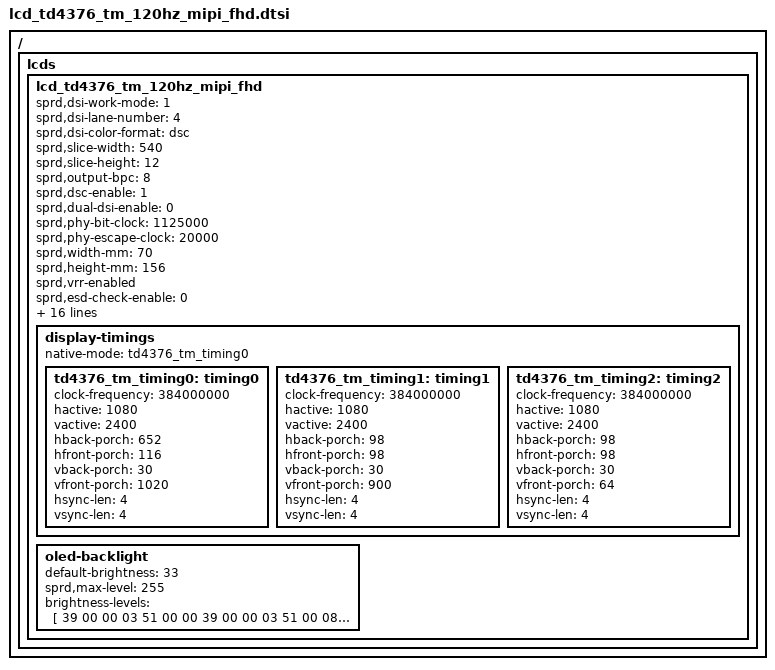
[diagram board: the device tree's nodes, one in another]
/ {
	fragment {
		target-path = "/";
		__overlay__ {
			lcds {
				lcd_td4376_tm_120hz_mipi_fhd: lcd_td4376_tm_120hz_mipi_fhd {

					sprd,dsi-work-mode = <1>; /* video burst mode*/
					sprd,dsi-lane-number = <4>;
					sprd,dsi-color-format = "dsc";
					sprd,slice-width = <540>;
					sprd,slice-height = <12>;
					sprd,output-bpc = <8>;
					sprd,dsc-enable = <1>;
					sprd,dual-dsi-enable = <0>;

					sprd,phy-bit-clock = <1125000>;
					sprd,phy-escape-clock = <20000>;/* kHz */
					sprd,width-mm = <70>;
					sprd,height-mm = <156>;
					sprd,vrr-enabled;
					sprd,esd-check-enable = <0>;
					sprd,esd-check-mode = <0>;
					sprd,esd-check-period = <2000>;
					sprd,esd-check-register = <0xA>;
					sprd,esd-check-value = <0x9c>;

					sprd,reset-on-sequence = <1 5>, <0 5>, <1 20>;
					sprd,reset-off-sequence = <0 10>;
					ontim,tp-reset-flag;
					sprd,need-execute-shutdown;
					ontim,qrcode-read-flag;
					sprd,qrcode-reg = <0xBF 27>;

					sprd,initial-command = [
						15 00 00 02 B0 04
						15 00 00 02 D6 00
						15 00 00 02 B0 00
						39 00 00 11 B6 30 6b 00 86 12 0a 13 1a 00 02 0a 0a 02 20 ff ff
						39 00 00 05 B7 51 00 00 00
						39 00 00 08 B8 57 3d 19 be 1e 0a 0a
						39 00 00 08 B9 6f 3d 28 be 3c 14 0a
						39 00 00 08 BA b5 33 41 be 64 23 0a
						39 00 00 0C BB 44 26 c3 1f 19 06 03 c0 00 00 10
						39 00 00 0C BC 32 4c c3 52 32 1f 03 f2 00 00 13
						39 00 00 0C BD 24 68 c3 aa 3f 32 03 ff 00 00 25
						39 00 00 0D BE 00 00 04 00 00 00 00 00 00 00 00 00
						39 00 00 24 C0 00 51 01 2c 08 09 60 03 BC 22 00 08 00 70 00 00 00 00 00 00 00 00 02 01 2c 01 2c 01 2c 00 00 00 00 00 00
						39 00 00 63 C1 30 00 00 61 00 00 00 00 22 00 05 20 00 80 fa 40 00 84 0f 00 00 00 00 00 00 00 00 00 00 00 00 00 00 00 00 00 00 00 00 00 00 01 2c 08 08 bf 07 d0 0b b8 0D 33 11 94 12 5c 1b 58 00 03 00 ff f5 84 7a a0 43 FE b3 4C 22 06 14 1B 62 F2 5F 0F e0 CB 2f f7 00 00 00 00 00 00 00 00 00 00 00 01 00 0e 37 d0
						39 00 00 A0 C2 00 60 20 01 04 10 05 05 00 00 00 00 00 00 00 00 00 00 00 00 00 00 00 00 00 00 00 00 60 46 04 04 01 01 c3 00 30 04 00 00 02 08 00 00 00 00 11 00 30 04 04 00 00 00 00 00 00 00 00 00 00 00 00 00 00 00 00 00 00 00 00 00 11 00 00 00 00 00 00 00 00 00 00 00 00 00 00 00 00 00 00 00 00 00 00 00 11 00 00 00 00 00 00 00 00 00 00 00 00 00 00 00 00 00 00 00 00 00 00 00 11 00 00 00 00 00 00 00 00 00 00 00 00 00 00 00 00 00 00 00 00 00 00 00 00 00 00 00 00 00 00 00 00 00 00 00 00 00 00
						39 00 00 6D C3 00 00 00 00 00 00 00 00 00 00 00 00 00 00 00 00 00 00 00 00 00 00 00 00 00 00 00 00 00 00 00 00 00 00 00 00 00 00 00 00 00 00 00 00 00 00 00 00 00 00 00 00 00 00 00 00 00 00 00 00 00 00 aa aa aa 00 00 00 00 00 00 00 00 00 00 00 00 00 00 c0 00 00 00 00 00 00 00 00 00 c0 00 00 00 00 00 00 00 00 00 00 00 00 00 00 00 00 00 00
						39 00 00 7B C4 00 00 00 5d 5f 61 00 00 00 5d 5f 61 50 02 0f 11 0e 10 bc bd 00 00 4c 51 00 00 00 5d 5f 61 00 00 00 5d 5f 61 50 02 0f 11 0e 10 bc bd 00 00 4c 51 ff ff ff ff ff ff 38 1e 4c 38 1e 4c 00 00 0c 00 00 0c 38 0e 00 38 0e 00 00 00 00 00 00 00 02 03 00 00 02 03 00 00 00 00 09 58 00 00 00 00 00 00 00 00 00 00 00 00 00 00 00 00 00 00 00 00 0E 00 00 0E 00 38 00 00 38 00 00 00
						39 00 00 06 C5 08 00 00 00 00
						39 00 00 58 C6 02 0a 43 ff ff ff ff 00 30 13 01 AF 0F 01 04 16 17 17 00 00 00 04 05 09 00 28 01 04 16 17 17 01 2b 00 00 00 1e 01 00 FF 00 00 00 00 20 20 00 00 12 00 00 00 00 00 22 22 00 00 00 00 10 00 01 00 00 00 00 01 00 00 00 00 01 00 00 00 00 05 00 1f 08 fc ff ff ff 01 00
						39 00 00 10 CB 20 80 70 00 20 00 00 2d 41 00 00 00 00 00 ff
						15 00 00 02 CD 00
						39 00 00 24 CE 5d 40 49 53 59 5e 63 68 6e 74 7e 8a 98 a8 bb d0 e7 ff 16 05 04 04 42 40 69 5a 40 40 00 00 00 84 fa 00 00
						39 00 00 07 CF 89 00 80 46 61 00
						39 00 00 13 D0 CB 1e d5 66 09 90 00 cf 0f 05 d1 e6 52 fe 09 09 c3 00
						39 00 00 3C D1 BC BC 1b b3 07 07 3b 55 35 55 35 05 77 7b 07 77 7b 78 d2 d2 06 96 BA 9C 22 22 22 b3 bb 80 00 bb bb 11 00 f8 c0 c0 c8 77 FF 11 55 55 05 55 05 55 05 55 05 77 77 77 05 05 30 33 ff
						39 00 00 18 D4 00 00 00 00 00 00 00 00 00 00 00 00 00 00 00 00 00 00 00 00 00 00 00
						39 00 00 50 D7 21 10 52 52 00 52 00 3c 10 52 04 fd 01 00 03 00 05 05 00 03 04 05 00 04 00 08 02 08 06 03 08 04 08 10 0c 0b 0a 0a 0a 07 07 06 06 00 08 08 04 05 09 00 04 04 04 04 04 04 04 00 04 04 04 04 04 04 04 04 04 04 06 06 05 05 05 00 00 00 00 00 00
						39 00 00 17 D9 40 99 26 ED 16 6C 16 6C 16 6C 00 14 00 14 00 14 01 0C 00 00 01 00
						39 00 00 05 DD 30 06 23 65
						39 00 00 0D DE 00 00 00 0F FF 00 00 00 00 10 00 51
						39 00 00 0B E6 00 00 00 00 00 00 00 00 00 00
						39 00 00 B7 E7 11 00 89 30 80 09 60 04 38 00 0c 02 1c 02 1c 02 00 02 0e 20 01 1F 00 07 0c 08 BB 08 7A 18 00 10 f0 03 0c 20 00 06 0b 0b 33 0e 1c 2a 38 46 54 62 69 70 77 79 7b 7d 7e 01 02 01 00 09 40 09 be 19 fc 19 fa 19 f8 1a 38 1a 78 1a b6 2a f6 2b 34 2b 74 3b 74 6b f4 00 00 00 00 00 00 11 00 89 30 80 09 60 04 38 00 0c 02 1c 02 1c 02 00 02 0e 20 01 1F 00 07 0c 08 BB 08 7A 18 00 10 f0 03 0c 20 00 06 0b 0b 33 0e 1c 2a 38 46 54 62 69 70 77 79 7b 7d 7e 01 02 01 00 09 40 09 be 19 fc 19 fa 19 f8 1a 38 1a 78 1a b6 2a f6 2b 34 2b 74 3b 74 6b f4 00 00 00 00 00 00
						39 00 00 05 E8 00 30 63 00
						39 00 00 26 EA 01 0e 02 00 0f A0 00 00 09 06 01 72 00 00 00 00 00 00 00 00 04 c2 00 12 00 51 05 10 86 00 00 00 00 00 00 00 00
						39 00 00 08 EB 00 00 00 00 01 00 11
						39 00 00 0B EC 05 00 00 10 66 0f A0 00 02 3a
						39 00 00 21 ED 01 01 02 02 08 08 09 09 00 00 00 00 02 00 00 00 00 00 00 00 00 00 00 d0 00 00 00 00 00 ec 10 00
						39 00 00 64 EE 01 3f 00 00 00 f4 03 00 00 00 00 d2 3f 00 00 00 00 00 00 00 00 00 00 00 7f fc 00 00 00 00 00 00 00 00 00 00 00 00 00 00 00 00 00 00 00 00 00 00 00 00 00 00 00 00 50 3f 00 00 00 00 00 00 00 00 00 00 00 00 00 00 00 00 00 00 00 00 00 00 00 00 00 00 00 00 00 00 00 00 00 00 00 00 00 00 00 00 3F 00 00
						39 00 00 71 EF 00 40 1d 03 30 00 00 00 00 14 10 12 00 00 00 00 00 00 00 00 00 00 40 1D 03 30 14 10 12 00 00 00 00 00 00 10 02 10 02 00 10 00 10 00 0a 06 00 00 00 00 00 4b 00 03 51 00 00 05 00 00 00 00 00 00 00 00 00 00 00 00 00 00 00 00 00 00 00 00 00 00 02 00 02 00 00 00 00 00 00 00 00 00 00 00 00 00 00 00 00 00 00 00 00 00 00 00 00 00 10 00 00 05
						39 00 00 08 F9 44 3F 00 8D BF 00 00
						15 00 00 02 B0 03
						15 00 00 02 B0 03
						15 00 00 02 35 00
						39 00 00 03 51 00 00
						15 00 00 02 53 2C
						15 00 00 02 55 00
						05 78 00 01 11
						05 0A 00 01 29
						];

					sprd,sleep-in-command = [
						05 0A 00 01 28
						05 78 00 01 10
						];
					sprd,sleep-out-command = [
						15 00 00 02 B0 04
						15 00 00 02 D6 00
						15 00 00 02 B0 00
						39 00 00 11 B6 30 6b 00 86 12 0a 13 1a 00 02 0a 0a 02 20 ff ff
						39 00 00 05 B7 51 00 00 00
						39 00 00 08 B8 57 3d 19 be 1e 0a 0a
						39 00 00 08 B9 6f 3d 28 be 3c 14 0a
						39 00 00 08 BA b5 33 41 be 64 23 0a
						39 00 00 0C BB 44 26 c3 1f 19 06 03 c0 00 00 10
						39 00 00 0C BC 32 4c c3 52 32 1f 03 f2 00 00 13
						39 00 00 0C BD 24 68 c3 aa 3f 32 03 ff 00 00 25
						39 00 00 0D BE 00 00 04 00 00 00 00 00 00 00 00 00
						39 00 00 24 C0 00 51 01 2c 08 09 60 03 BC 22 00 08 00 70 00 00 00 00 00 00 00 00 02 01 2c 01 2c 01 2c 00 00 00 00 00 00
						39 00 00 63 C1 30 00 00 71 00 00 00 00 22 00 05 20 00 80 fa 40 00 84 0f 00 00 00 00 00 00 00 00 00 00 00 00 00 00 00 00 00 00 00 00 00 00 01 2c 08 08 bf 07 d0 0b b8 0D 33 11 94 12 5c 1b 58 00 03 00 ff f5 84 7a a0 43 FE b3 4C 22 06 14 1B 62 F2 5F 0F e0 CB 2f f7 00 00 00 00 00 00 00 00 00 00 00 01 00 0e 37 d0
						39 00 00 A0 C2 00 60 20 01 04 10 05 05 00 00 00 00 00 00 00 00 00 00 00 00 00 00 00 00 00 00 00 00 60 46 04 04 01 01 c3 00 30 04 00 00 02 08 00 00 00 00 11 00 30 04 04 00 00 00 00 00 00 00 00 00 00 00 00 00 00 00 00 00 00 00 00 00 11 00 00 00 00 00 00 00 00 00 00 00 00 00 00 00 00 00 00 00 00 00 00 00 11 00 00 00 00 00 00 00 00 00 00 00 00 00 00 00 00 00 00 00 00 00 00 00 11 00 00 00 00 00 00 00 00 00 00 00 00 00 00 00 00 00 00 00 00 00 00 00 00 00 00 00 00 00 00 00 00 00 00 00 00 00 00
						39 00 00 6D C3 00 00 00 00 00 00 00 00 00 00 00 00 00 00 00 00 00 00 00 00 00 00 00 00 00 00 00 00 00 00 00 00 00 00 00 00 00 00 00 00 00 00 00 00 00 00 00 00 00 00 00 00 00 00 00 00 00 00 00 00 00 00 aa aa aa 00 00 00 00 00 00 00 00 00 00 00 00 00 00 c0 00 00 00 00 00 00 00 00 00 c0 00 00 00 00 00 00 00 00 00 00 00 00 00 00 00 00 00 00
						39 00 00 7B C4 00 00 00 5d 5f 61 00 00 00 5d 5f 61 50 02 0f 11 0e 10 bc bd 00 00 4c 51 00 00 00 5d 5f 61 00 00 00 5d 5f 61 50 02 0f 11 0e 10 bc bd 00 00 4c 51 ff ff ff ff ff ff 38 1e 4c 38 1e 4c 00 00 0c 00 00 0c 38 0e 00 38 0e 00 00 00 00 00 00 00 02 03 00 00 02 03 00 00 00 00 09 58 00 00 00 00 00 00 00 00 00 00 00 00 00 00 00 00 00 00 00 00 0E 00 00 0E 00 38 00 00 38 00 00 00
						39 00 00 06 C5 08 00 00 00 00
						39 00 00 58 C6 02 0a 43 ff ff ff ff 00 30 13 01 AF 0F 01 04 16 17 17 00 00 00 04 05 09 00 28 01 04 16 17 17 01 2b 00 00 00 1e 01 00 FF 00 00 00 00 20 20 00 00 12 00 00 00 00 00 22 22 00 00 00 00 10 00 01 00 00 00 00 01 00 00 00 00 01 00 00 00 00 05 00 1f 08 fc ff ff ff 01 00
						39 00 00 10 CB 20 80 70 00 20 00 00 2d 41 00 00 00 00 00 ff
						15 00 00 02 CD 00
						39 00 00 24 CE 5d 40 49 53 59 5e 63 68 6e 74 7e 8a 98 a8 bb d0 e7 ff 16 05 04 04 42 40 69 5a 40 40 00 00 00 84 fa 00 00
						39 00 00 07 CF 89 00 80 46 61 00
						39 00 00 13 D0 CB 1e d5 66 09 90 00 cf 0f 05 d1 e6 52 fe 09 09 c3 00
						39 00 00 3C D1 BC BC 1b b3 07 07 3b 55 35 55 35 05 77 7b 07 77 7b 78 d2 d2 06 96 BA 9C 22 22 22 b3 bb 80 00 bb bb 11 00 f8 c0 c0 c8 77 FF 11 55 55 05 55 05 55 05 55 05 77 77 77 05 05 30 33 ff
						39 00 00 18 D4 00 00 00 00 00 00 00 00 00 00 00 00 00 00 00 00 00 00 00 00 00 00 00
						39 00 00 50 D7 21 10 52 52 00 52 00 3c 10 52 04 fd 01 00 03 00 05 05 00 03 04 05 00 04 00 08 02 08 06 03 08 04 08 10 0c 0b 0a 0a 0a 07 07 06 06 00 08 08 04 05 09 00 04 04 04 04 04 04 04 00 04 04 04 04 04 04 04 04 04 04 06 06 05 05 05 00 00 00 00 00 00
						39 00 00 17 D9 40 99 26 ED 16 6C 16 6C 16 6C 00 14 00 14 00 14 01 0C 00 00 01 00
						39 00 00 05 DD 30 06 23 65
						39 00 00 0D DE 00 00 00 0F FF 00 00 00 00 10 00 51
						39 00 00 0B E6 00 00 00 00 00 00 00 00 00 00
						39 00 00 B7 E7 11 00 89 30 80 09 60 04 38 00 0c 02 1c 02 1c 02 00 02 0e 20 01 1F 00 07 0c 08 BB 08 7A 18 00 10 f0 03 0c 20 00 06 0b 0b 33 0e 1c 2a 38 46 54 62 69 70 77 79 7b 7d 7e 01 02 01 00 09 40 09 be 19 fc 19 fa 19 f8 1a 38 1a 78 1a b6 2a f6 2b 34 2b 74 3b 74 6b f4 00 00 00 00 00 00 11 00 89 30 80 09 60 04 38 00 0c 02 1c 02 1c 02 00 02 0e 20 01 1F 00 07 0c 08 BB 08 7A 18 00 10 f0 03 0c 20 00 06 0b 0b 33 0e 1c 2a 38 46 54 62 69 70 77 79 7b 7d 7e 01 02 01 00 09 40 09 be 19 fc 19 fa 19 f8 1a 38 1a 78 1a b6 2a f6 2b 34 2b 74 3b 74 6b f4 00 00 00 00 00 00
						39 00 00 05 E8 00 30 63 00
						39 00 00 26 EA 01 0e 02 00 0f A0 00 00 09 06 01 72 00 00 00 00 00 00 00 00 04 c2 00 12 00 51 05 10 86 00 00 00 00 00 00 00 00
						39 00 00 08 EB 00 00 00 00 01 00 11
						39 00 00 0B EC 05 00 00 10 66 0f A0 00 02 3a
						39 00 00 21 ED 01 01 02 02 08 08 09 09 00 00 00 00 02 00 00 00 00 00 00 00 00 00 00 d0 00 00 00 00 00 ec 10 00
						39 00 00 64 EE 01 3f 00 00 00 f4 03 00 00 00 00 d2 3f 00 00 00 00 00 00 00 00 00 00 00 7f fc 00 00 00 00 00 00 00 00 00 00 00 00 00 00 00 00 00 00 00 00 00 00 00 00 00 00 00 00 50 3f 00 00 00 00 00 00 00 00 00 00 00 00 00 00 00 00 00 00 00 00 00 00 00 00 00 00 00 00 00 00 00 00 00 00 00 00 00 00 00 00 3F 00 00
						39 00 00 71 EF 00 40 1d 03 30 00 00 00 00 14 10 12 00 00 00 00 00 00 00 00 00 00 40 1D 03 30 14 10 12 00 00 00 00 00 00 10 02 10 02 00 10 00 10 00 0a 06 00 00 00 00 00 4b 00 03 51 00 00 05 00 00 00 00 00 00 00 00 00 00 00 00 00 00 00 00 00 00 00 00 00 00 02 00 02 00 00 00 00 00 00 00 00 00 00 00 00 00 00 00 00 00 00 00 00 00 00 00 00 00 10 00 00 05
						39 00 00 08 F9 44 3F 00 8D BF 00 00
						15 00 00 02 B0 03
						15 00 00 02 B0 03
						15 00 00 02 35 00
						39 00 00 03 51 00 00
						15 00 00 02 53 2C
						15 00 00 02 55 00
						05 78 00 01 11
						05 0A 00 01 29
						];

					display-timings {
						native-mode = <&td4376_tm_timing0>;
						td4376_tm_timing0: timing0 {
							clock-frequency = <384000000>;
							hactive = <1080>;
							vactive = <2400>;
							hback-porch = <652>;
							hfront-porch = <116>;
							vback-porch = <30>;
							vfront-porch = <1020>;
							hsync-len = <4>;
							vsync-len = <4>;
						};
						td4376_tm_timing1: timing1 {
							clock-frequency = <384000000>;
							hactive = <1080>;
							vactive = <2400>;
							hback-porch = <98>;
							hfront-porch = <98>;
							vback-porch = <30>;
							vfront-porch = <900>;
							hsync-len = <4>;
							vsync-len = <4>;
						};
						td4376_tm_timing2: timing2 {
							clock-frequency = <384000000>;
							hactive = <1080>;
							vactive = <2400>;
							hback-porch = <98>;
							hfront-porch = <98>;
							vback-porch = <30>;
							vfront-porch = <64>;
							hsync-len = <4>;
							vsync-len = <4>;
						};
					};
					oled-backlight {
						default-brightness = <33>;
						sprd,max-level = <255>;
						brightness-levels = [
							39 00 00 03 51 00 00
							39 00 00 03 51 00 08
							39 00 00 03 51 00 10
							39 00 00 03 51 00 18
							39 00 00 03 51 00 20
							39 00 00 03 51 00 28
							39 00 00 03 51 00 30
							39 00 00 03 51 00 38
							39 00 00 03 51 00 40
							39 00 00 03 51 00 48
							39 00 00 03 51 00 50
							39 00 00 03 51 00 58
							39 00 00 03 51 00 60
							39 00 00 03 51 00 68
							39 00 00 03 51 00 70
							39 00 00 03 51 00 78
							39 00 00 03 51 00 80
							39 00 00 03 51 00 88
							39 00 00 03 51 00 90
							39 00 00 03 51 00 98
							39 00 00 03 51 00 A0
							39 00 00 03 51 00 A8
							39 00 00 03 51 00 B0
							39 00 00 03 51 00 B8
							39 00 00 03 51 00 C0
							39 00 00 03 51 00 C8
							39 00 00 03 51 00 D0
							39 00 00 03 51 00 D8
							39 00 00 03 51 00 E0
							39 00 00 03 51 00 E8
							39 00 00 03 51 00 F0
							39 00 00 03 51 00 F8
							39 00 00 03 51 01 00
							39 00 00 03 51 01 08
							39 00 00 03 51 01 10
							39 00 00 03 51 01 18
							39 00 00 03 51 01 20
							39 00 00 03 51 01 28
							39 00 00 03 51 01 30
							39 00 00 03 51 01 38
							39 00 00 03 51 01 40
							39 00 00 03 51 01 48
							39 00 00 03 51 01 50
							39 00 00 03 51 01 58
							39 00 00 03 51 01 60
							39 00 00 03 51 01 68
							39 00 00 03 51 01 70
							39 00 00 03 51 01 78
							39 00 00 03 51 01 80
							39 00 00 03 51 01 88
							39 00 00 03 51 01 90
							39 00 00 03 51 01 98
							39 00 00 03 51 01 A0
							39 00 00 03 51 01 A8
							39 00 00 03 51 01 B0
							39 00 00 03 51 01 B8
							39 00 00 03 51 01 C0
							39 00 00 03 51 01 C8
							39 00 00 03 51 01 D0
							39 00 00 03 51 01 D8
							39 00 00 03 51 01 E0
							39 00 00 03 51 01 E8
							39 00 00 03 51 01 F0
							39 00 00 03 51 01 F8
							39 00 00 03 51 02 00
							39 00 00 03 51 02 08
							39 00 00 03 51 02 10
							39 00 00 03 51 02 18
							39 00 00 03 51 02 20
							39 00 00 03 51 02 28
							39 00 00 03 51 02 30
							39 00 00 03 51 02 38
							39 00 00 03 51 02 40
							39 00 00 03 51 02 48
							39 00 00 03 51 02 50
							39 00 00 03 51 02 58
							39 00 00 03 51 02 60
							39 00 00 03 51 02 68
							39 00 00 03 51 02 70
							39 00 00 03 51 02 78
							39 00 00 03 51 02 80
							39 00 00 03 51 02 88
							39 00 00 03 51 02 90
							39 00 00 03 51 02 98
							39 00 00 03 51 02 A0
							39 00 00 03 51 02 A8
							39 00 00 03 51 02 B0
							39 00 00 03 51 02 B8
							39 00 00 03 51 02 C0
							39 00 00 03 51 02 C8
							39 00 00 03 51 02 D0
							39 00 00 03 51 02 D8
							39 00 00 03 51 02 E0
							39 00 00 03 51 02 E8
							39 00 00 03 51 02 F0
							39 00 00 03 51 02 F8
							39 00 00 03 51 03 00
							39 00 00 03 51 03 08
							39 00 00 03 51 03 10
							39 00 00 03 51 03 18
							39 00 00 03 51 03 20
							39 00 00 03 51 03 28
							39 00 00 03 51 03 30
							39 00 00 03 51 03 38
							39 00 00 03 51 03 40
							39 00 00 03 51 03 48
							39 00 00 03 51 03 50
							39 00 00 03 51 03 58
							39 00 00 03 51 03 60
							39 00 00 03 51 03 68
							39 00 00 03 51 03 70
							39 00 00 03 51 03 78
							39 00 00 03 51 03 80
							39 00 00 03 51 03 88
							39 00 00 03 51 03 90
							39 00 00 03 51 03 98
							39 00 00 03 51 03 A0
							39 00 00 03 51 03 A8
							39 00 00 03 51 03 B0
							39 00 00 03 51 03 B8
							39 00 00 03 51 03 C0
							39 00 00 03 51 03 C8
							39 00 00 03 51 03 D0
							39 00 00 03 51 03 D8
							39 00 00 03 51 03 E0
							39 00 00 03 51 03 E8
							39 00 00 03 51 03 F0
							39 00 00 03 51 03 F8
							39 00 00 03 51 04 00
							39 00 00 03 51 04 08
							39 00 00 03 51 04 10
							39 00 00 03 51 04 18
							39 00 00 03 51 04 20
							39 00 00 03 51 04 28
							39 00 00 03 51 04 30
							39 00 00 03 51 04 38
							39 00 00 03 51 04 40
							39 00 00 03 51 04 48
							39 00 00 03 51 04 50
							39 00 00 03 51 04 58
							39 00 00 03 51 04 60
							39 00 00 03 51 04 68
							39 00 00 03 51 04 70
							39 00 00 03 51 04 78
							39 00 00 03 51 04 80
							39 00 00 03 51 04 88
							39 00 00 03 51 04 90
							39 00 00 03 51 04 98
							39 00 00 03 51 04 A0
							39 00 00 03 51 04 A8
							39 00 00 03 51 04 B0
							39 00 00 03 51 04 B8
							39 00 00 03 51 04 C0
							39 00 00 03 51 04 C8
							39 00 00 03 51 04 D0
							39 00 00 03 51 04 D8
							39 00 00 03 51 04 E0
							39 00 00 03 51 04 E8
							39 00 00 03 51 04 F0
							39 00 00 03 51 04 F8
							39 00 00 03 51 05 00
							39 00 00 03 51 05 08
							39 00 00 03 51 05 10
							39 00 00 03 51 05 18
							39 00 00 03 51 05 20
							39 00 00 03 51 05 28
							39 00 00 03 51 05 30
							39 00 00 03 51 05 38
							39 00 00 03 51 05 40
							39 00 00 03 51 05 48
							39 00 00 03 51 05 50
							39 00 00 03 51 05 58
							39 00 00 03 51 05 60
							39 00 00 03 51 05 68
							39 00 00 03 51 05 70
							39 00 00 03 51 05 78
							39 00 00 03 51 05 80
							39 00 00 03 51 05 88
							39 00 00 03 51 05 90
							39 00 00 03 51 05 98
							39 00 00 03 51 05 A0
							39 00 00 03 51 05 A8
							39 00 00 03 51 05 B0
							39 00 00 03 51 05 B8
							39 00 00 03 51 05 C0
							39 00 00 03 51 05 C8
							39 00 00 03 51 05 D0
							39 00 00 03 51 05 D8
							39 00 00 03 51 05 E0
							39 00 00 03 51 05 E8
							39 00 00 03 51 05 F0
							39 00 00 03 51 05 F8
							39 00 00 03 51 06 00
							39 00 00 03 51 06 08
							39 00 00 03 51 06 10
							39 00 00 03 51 06 18
							39 00 00 03 51 06 20
							39 00 00 03 51 06 28
							39 00 00 03 51 06 30
							39 00 00 03 51 06 38
							39 00 00 03 51 06 40
							39 00 00 03 51 06 48
							39 00 00 03 51 06 50
							39 00 00 03 51 06 58
							39 00 00 03 51 06 60
							39 00 00 03 51 06 68
							39 00 00 03 51 06 70
							39 00 00 03 51 06 78
							39 00 00 03 51 06 80
							39 00 00 03 51 06 88
							39 00 00 03 51 06 90
							39 00 00 03 51 06 98
							39 00 00 03 51 06 A0
							39 00 00 03 51 06 A8
							39 00 00 03 51 06 B0
							39 00 00 03 51 06 B8
							39 00 00 03 51 06 C0
							39 00 00 03 51 06 C8
							39 00 00 03 51 06 D0
							39 00 00 03 51 06 D8
							39 00 00 03 51 06 E0
							39 00 00 03 51 06 E8
							39 00 00 03 51 06 F0
							39 00 00 03 51 06 F8
							39 00 00 03 51 07 00
							39 00 00 03 51 07 08
							39 00 00 03 51 07 10
							39 00 00 03 51 07 18
							39 00 00 03 51 07 20
							39 00 00 03 51 07 28
							39 00 00 03 51 07 30
							39 00 00 03 51 07 38
							39 00 00 03 51 07 40
							39 00 00 03 51 07 48
							39 00 00 03 51 07 50
							39 00 00 03 51 07 58
							39 00 00 03 51 07 60
							39 00 00 03 51 07 68
							39 00 00 03 51 07 70
							39 00 00 03 51 07 78
							39 00 00 03 51 07 80
							39 00 00 03 51 07 88
							39 00 00 03 51 07 90
							39 00 00 03 51 07 98
							39 00 00 03 51 07 A0
							39 00 00 03 51 07 A8
							39 00 00 03 51 07 B0
							39 00 00 03 51 07 B8
							39 00 00 03 51 07 C0
							39 00 00 03 51 07 C8
							39 00 00 03 51 07 D0
							39 00 00 03 51 07 D8
							39 00 00 03 51 07 E0
							39 00 00 03 51 07 E8
							39 00 00 03 51 07 F4
							39 00 00 03 51 07 FF
						];
					};
				};
			};
		};
	};
};
